# STM32H733 register map
File version: 1.9
CPU: CM7 r0p1, little endian, MPU, FPU, 4 interrupt priority bits
Registers are 32-bit, read-write, reset 0x0 unless marked. A register's access mark holds for its fields unless they carry their own. Offsets are from the block's base; [hi:lo] are bit positions; {n}, {i} and the like mark numbered series; 'fields as' and 'values as' point back to an identical list.

## MDIOS — Management data input/output slave
Base 0x40009400
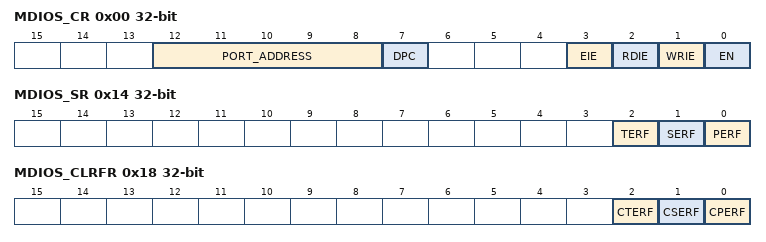
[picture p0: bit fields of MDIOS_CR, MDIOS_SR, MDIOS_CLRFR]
0x00 MDIOS_CR — MDIOS configuration register
  [12:8] PORT_ADDRESS — Slaves's address
  [7] DPC — Disable Preamble Check
  [3] EIE — Error interrupt enable
  [2] RDIE — Register Read Interrupt Enable
  [1] WRIE — Register write interrupt enable
  [0] EN — Peripheral enable
0x04 MDIOS_WRFR ro — MDIOS write flag register
  [31:0] WRF — Write flags for MDIO registers 0 to 31
0x08 MDIOS_CWRFR — MDIOS clear write flag register
  [31:0] CWRF — Clear the write flag
0x0C MDIOS_RDFR ro — MDIOS read flag register
  [31:0] RDF — Read flags for MDIO registers 0 to 31
0x10 MDIOS_CRDFR — MDIOS clear read flag register
  [31:0] CRDF — Clear the read flag
0x14 MDIOS_SR ro — MDIOS status register
  [2] TERF — Turnaround error flag
  [1] SERF — Start error flag
  [0] PERF — Preamble error flag
0x18 MDIOS_CLRFR — MDIOS clear flag register
  [2] CTERF — Clear the turnaround error flag
  [1] CSERF — Clear the start error flag
  [0] CPERF — Clear the preamble error flag
{0x1C+4i} MDIOS_DINR{i} ro (i=0..31) — MDIOS input data register {i}
  [15:0] DIN{i} — Input data received from MDIO Master during write frames
{0x9C+4i} MDIOS_DOUTR{i} (i=0..31) — MDIOS output data register {i}
  [15:0] DOUT{i} — Output data sent to MDIO Master during read frames

## OPAMP — Operational amplifiers
Base 0x40009000
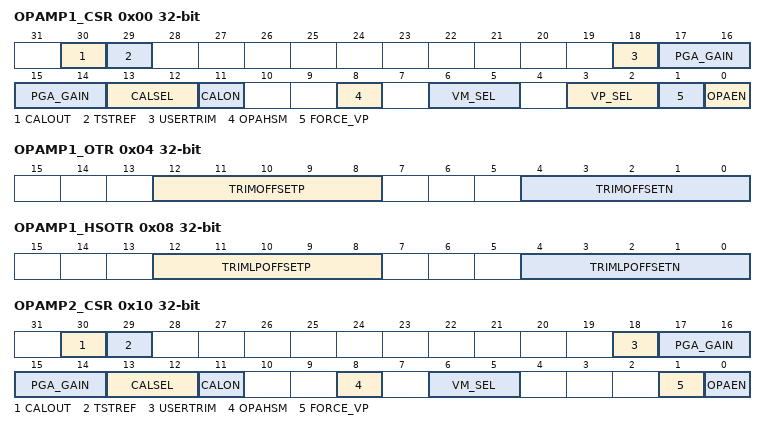
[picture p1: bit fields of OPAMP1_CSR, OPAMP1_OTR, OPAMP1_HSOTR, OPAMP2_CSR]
0x00 OPAMP1_CSR — OPAMP1 control/status register
  [30] CALOUT — Operational amplifier calibration output
  [29] TSTREF — OPAMP calibration reference voltage output control (reserved for test)
  [18] USERTRIM — User trimming enable
  [17:14] PGA_GAIN — allows to switch from AOP offset trimmed values to AOP offset
  [13:12] CALSEL — Calibration selection
  [11] CALON — Calibration mode enabled
  [8] OPAHSM — Operational amplifier high-speed mode
  [6:5] VM_SEL — Inverting input selection
  [3:2] VP_SEL — Operational amplifier PGA mode
  [1] FORCE_VP — Force internal reference on VP (reserved for test
  [0] OPAEN — Operational amplifier Enable
0x04 OPAMP1_OTR — OPAMP1 offset trimming register in normal mode
  [12:8] TRIMOFFSETP — Trim for PMOS differential pairs
  [4:0] TRIMOFFSETN — Trim for NMOS differential pairs
0x08 OPAMP1_HSOTR — OPAMP1 offset trimming register in low-power mode
  [12:8] TRIMLPOFFSETP — Trim for PMOS differential pairs
  [4:0] TRIMLPOFFSETN — Trim for NMOS differential pairs
0x10 OPAMP2_CSR — OPAMP2 control/status register
  [30] CALOUT — Operational amplifier calibration output
  [29] TSTREF — OPAMP calibration reference voltage output control (reserved for test)
  [18] USERTRIM — User trimming enable
  [17:14] PGA_GAIN — Operational amplifier Programmable amplifier gain value
  [13:12] CALSEL — Calibration selection
  [11] CALON — Calibration mode enabled
  [8] OPAHSM — Operational amplifier high-speed mode
  [6:5] VM_SEL — Inverting input selection
  [1] FORCE_VP — Force internal reference on VP (reserved for test)
  [0] OPAEN — Operational amplifier Enable
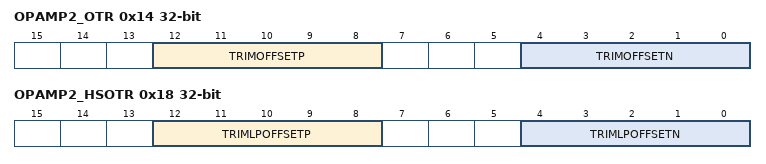
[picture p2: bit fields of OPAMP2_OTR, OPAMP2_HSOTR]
0x14 OPAMP2_OTR — OPAMP2 offset trimming register in normal mode
  fields as OPAMP1_OTR
0x18 OPAMP2_HSOTR — OPAMP2 offset trimming register in low-power mode
  fields as OPAMP1_HSOTR

## OTG1_HS_PWRCLK — USB 1 on the go high speed
Base 0x40040E00
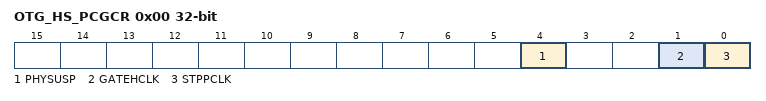
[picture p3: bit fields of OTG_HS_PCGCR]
0x00 OTG_HS_PCGCR — Power and clock gating control register
  [4] PHYSUSP — PHY suspended
  [1] GATEHCLK
  [0] STPPCLK — Stop PHY clock

## OctoSPII_O_Manager
Base 0x5200B400
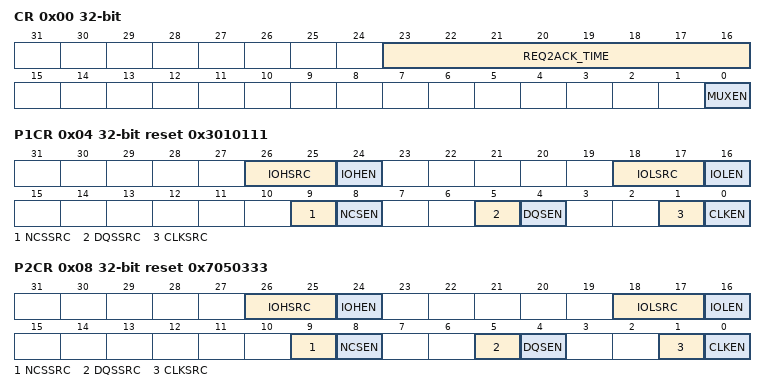
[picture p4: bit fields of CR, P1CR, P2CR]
0x00 CR — OctoSPI IO Manager Control Register
  [23:16] REQ2ACK_TIME — REQ to ACK Time
  [0] MUXEN — Multiplexed mode Enable
0x04 P1CR reset 0x3010111 — OctoSPI IO Manager Port 1 configuration register
  [26:25] IOHSRC
  [24] IOHEN
  [18:17] IOLSRC
  [16] IOLEN
  [9] NCSSRC
  [8] NCSEN
  [5] DQSSRC
  [4] DQSEN
  [1] CLKSRC — CLK/CLKn Source for Port n
  [0] CLKEN — CLK/CLKn Enable for Port n
0x08 P2CR reset 0x7050333 — OctoSPI IO Manager Port 2 configuration register
  [26:25] IOHSRC, [24] IOHEN, [18:17] IOLSRC, [16] IOLEN, [9] NCSSRC, [8] NCSEN, [5] DQSSRC, [4] DQSEN, [1] CLKSRC, [0] CLKEN

## Notices in the file
Copyright (c) 2025 STMicroelectronics.
SPDX-License-Identifier: Apache-2.0
Licensed under the Apache License, Version 2.0 (the "License");
you may not use this file except in compliance with the License.
You may obtain a copy of the License at
http://www.apache.org/licenses/LICENSE-2.0
Unless required by applicable law or agreed to in writing, software
distributed under the License is distributed on an "AS IS" BASIS,
WITHOUT WARRANTIES OR CONDITIONS OF ANY KIND, either express or implied.
See the License for the specific language governing permissions and
limitations under the License.
